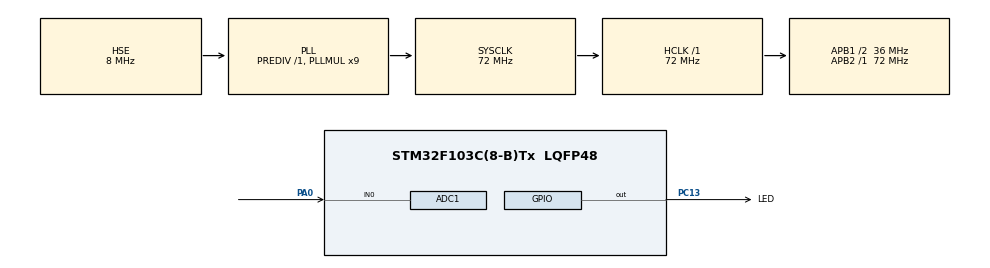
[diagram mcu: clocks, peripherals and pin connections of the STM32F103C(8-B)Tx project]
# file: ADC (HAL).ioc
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ADC1.Channel-0\#ChannelRegularConversion=ADC_CHANNEL_0
ADC1.ExternalTrigConv=ADC_EXTERNALTRIGCONV_T3_TRGO
ADC1.NbrOfConversionFlag=1
ADC1.Rank-0\#ChannelRegularConversion=1
ADC1.SamplingTime-0\#ChannelRegularConversion=ADC_SAMPLETIME_1CYCLE_5
ADC1.master=1
Mcu.Family=STM32F1
Mcu.Name=STM32F103C(8-B)Tx
Mcu.Package=LQFP48
NVIC.ADC1_2_IRQn=true\:0\:0\:false\:false\:true\:true\:true
NVIC.PriorityGroup=NVIC_PRIORITYGROUP_4
PA0-WKUP.Signal=ADCx_IN0
PA13.Mode=Serial_Wire
PA13.Signal=SYS_JTMS-SWDIO
PA14.Mode=Serial_Wire
PA14.Signal=SYS_JTCK-SWCLK
PC13-TAMPER-RTC.GPIO_Label=LED
PC13-TAMPER-RTC.Signal=GPIO_Output
PD0-OSC_IN.Mode=HSE-External-Oscillator
PD0-OSC_IN.Signal=RCC_OSC_IN
PD1-OSC_OUT.Mode=HSE-External-Oscillator
PD1-OSC_OUT.Signal=RCC_OSC_OUT
ProjectManager.HeapSize=0x200
ProjectManager.StackSize=0x400
ProjectManager.TargetToolchain=EWARM V8.32
RCC.ADCPresc=RCC_ADCPCLK2_DIV6
RCC.AHBFreq_Value=72000000
RCC.APB1CLKDivider=RCC_HCLK_DIV2
RCC.APB1Freq_Value=36000000
RCC.APB1TimFreq_Value=72000000
RCC.APB2Freq_Value=72000000
RCC.APB2TimFreq_Value=72000000
RCC.HCLKFreq_Value=72000000
RCC.PLLMUL=RCC_PLL_MUL9
RCC.PLLSourceVirtual=RCC_PLLSOURCE_HSE
RCC.RTCClockSelection=RCC_RTCCLKSOURCE_LSE
RCC.SYSCLKFreq_VALUE=72000000
RCC.SYSCLKSource=RCC_SYSCLKSOURCE_PLLCLK
RCC.USBFreq_Value=72000000
SH.ADCx_IN0.0=ADC1_IN0,IN0
TIM3.AutoReloadPreload=TIM_AUTORELOAD_PRELOAD_ENABLE
TIM3.Period=2000
TIM3.Prescaler=36000
TIM3.TIM_MasterOutputTrigger=TIM_TRGO_UPDATE
VP_TIM3_VS_ClockSourceINT.Mode=Internal
board=custom

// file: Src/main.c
/* USER CODE BEGIN Header */
/**
  ******************************************************************************
  * @file           : main.c
  * @brief          : Main program body
  ******************************************************************************
  * @attention
  *
  * <h2><center>&copy; Copyright (c) 2019 STMicroelectronics.
  * All rights reserved.</center></h2>
  *
  * This software component is licensed by ST under BSD 3-Clause license,
  * the "License"; You may not use this file except in compliance with the
  * License. You may obtain a copy of the License at:
  *                        opensource.org/licenses/BSD-3-Clause
  *
  ******************************************************************************
  */
/* USER CODE END Header */

#include "main.h"

ADC_HandleTypeDef hadc1;

TIM_HandleTypeDef htim3;

void SystemClock_Config(void);
static void MX_GPIO_Init(void);
static void MX_ADC1_Init(void);
static void MX_TIM3_Init(void);

int main(void)
{

  /* MCU Configuration--------------------------------------------------------*/

  /* Reset of all peripherals, Initializes the Flash interface and the Systick. */
  HAL_Init();

  /* Configure the system clock */
  SystemClock_Config();

  /* Initialize all configured peripherals */
  MX_GPIO_Init();
  MX_ADC1_Init();
  MX_TIM3_Init();
  /* USER CODE BEGIN 2 */
  HAL_ADCEx_Calibration_Start(&hadc1);
  HAL_ADC_Start_IT(&hadc1);
  //HAL_TIM_Base_Start_IT(&htim3);
  HAL_TIM_Base_Start(&htim3);
  /* USER CODE END 2 */

  /* Infinite loop */
  while (1)
  {

  }
}

void SystemClock_Config(void)
{
  RCC_OscInitTypeDef RCC_OscInitStruct = {0};
  RCC_ClkInitTypeDef RCC_ClkInitStruct = {0};
  RCC_PeriphCLKInitTypeDef PeriphClkInit = {0};

  /** Initializes the CPU, AHB and APB busses clocks
  */
  RCC_OscInitStruct.OscillatorType = RCC_OSCILLATORTYPE_HSE;
  RCC_OscInitStruct.HSEState = RCC_HSE_ON;
  RCC_OscInitStruct.HSEPredivValue = RCC_HSE_PREDIV_DIV1;
  RCC_OscInitStruct.HSIState = RCC_HSI_ON;
  RCC_OscInitStruct.PLL.PLLState = RCC_PLL_ON;
  RCC_OscInitStruct.PLL.PLLSource = RCC_PLLSOURCE_HSE;
  RCC_OscInitStruct.PLL.PLLMUL = RCC_PLL_MUL9;
  if (HAL_RCC_OscConfig(&RCC_OscInitStruct) != HAL_OK)
  {
    Error_Handler();
  }
  /** Initializes the CPU, AHB and APB busses clocks
  */
  RCC_ClkInitStruct.ClockType = RCC_CLOCKTYPE_HCLK|RCC_CLOCKTYPE_SYSCLK
                              |RCC_CLOCKTYPE_PCLK1|RCC_CLOCKTYPE_PCLK2;
  RCC_ClkInitStruct.SYSCLKSource = RCC_SYSCLKSOURCE_PLLCLK;
  RCC_ClkInitStruct.AHBCLKDivider = RCC_SYSCLK_DIV1;
  RCC_ClkInitStruct.APB1CLKDivider = RCC_HCLK_DIV2;
  RCC_ClkInitStruct.APB2CLKDivider = RCC_HCLK_DIV1;

  if (HAL_RCC_ClockConfig(&RCC_ClkInitStruct, FLASH_LATENCY_2) != HAL_OK)
  {
    Error_Handler();
  }
  PeriphClkInit.PeriphClockSelection = RCC_PERIPHCLK_ADC;
  PeriphClkInit.AdcClockSelection = RCC_ADCPCLK2_DIV6;
  if (HAL_RCCEx_PeriphCLKConfig(&PeriphClkInit) != HAL_OK)
  {
    Error_Handler();
  }
}

static void MX_ADC1_Init(void)
{

  ADC_ChannelConfTypeDef sConfig = {0};

  /** Common config
  */
  hadc1.Instance = ADC1;
  hadc1.Init.ScanConvMode = ADC_SCAN_DISABLE;
  hadc1.Init.ContinuousConvMode = DISABLE;
  hadc1.Init.DiscontinuousConvMode = DISABLE;
  hadc1.Init.ExternalTrigConv = ADC_EXTERNALTRIGCONV_T3_TRGO;
  hadc1.Init.DataAlign = ADC_DATAALIGN_RIGHT;
  hadc1.Init.NbrOfConversion = 1;
  if (HAL_ADC_Init(&hadc1) != HAL_OK)
  {
    Error_Handler();
  }
  /** Configure Regular Channel
  */
  sConfig.Channel = ADC_CHANNEL_0;
  sConfig.Rank = ADC_REGULAR_RANK_1;
  sConfig.SamplingTime = ADC_SAMPLETIME_1CYCLE_5;
  if (HAL_ADC_ConfigChannel(&hadc1, &sConfig) != HAL_OK)
  {
    Error_Handler();
  }

}

static void MX_TIM3_Init(void)
{

  TIM_ClockConfigTypeDef sClockSourceConfig = {0};
  TIM_MasterConfigTypeDef sMasterConfig = {0};

  htim3.Instance = TIM3;
  htim3.Init.Prescaler = 36000;
  htim3.Init.CounterMode = TIM_COUNTERMODE_UP;
  htim3.Init.Period = 2000;
  htim3.Init.ClockDivision = TIM_CLOCKDIVISION_DIV1;
  htim3.Init.AutoReloadPreload = TIM_AUTORELOAD_PRELOAD_ENABLE;
  if (HAL_TIM_Base_Init(&htim3) != HAL_OK)
  {
    Error_Handler();
  }
  sClockSourceConfig.ClockSource = TIM_CLOCKSOURCE_INTERNAL;
  if (HAL_TIM_ConfigClockSource(&htim3, &sClockSourceConfig) != HAL_OK)
  {
    Error_Handler();
  }
  sMasterConfig.MasterOutputTrigger = TIM_TRGO_UPDATE;
  sMasterConfig.MasterSlaveMode = TIM_MASTERSLAVEMODE_DISABLE;
  if (HAL_TIMEx_MasterConfigSynchronization(&htim3, &sMasterConfig) != HAL_OK)
  {
    Error_Handler();
  }

}

static void MX_GPIO_Init(void)
{
  GPIO_InitTypeDef GPIO_InitStruct = {0};

  /* GPIO Ports Clock Enable */
  __HAL_RCC_GPIOC_CLK_ENABLE();
  __HAL_RCC_GPIOD_CLK_ENABLE();
  __HAL_RCC_GPIOA_CLK_ENABLE();

  /*Configure GPIO pin Output Level */
  HAL_GPIO_WritePin(LED_GPIO_Port, LED_Pin, GPIO_PIN_RESET);

  /*Configure GPIO pin : LED_Pin */
  GPIO_InitStruct.Pin = LED_Pin;
  GPIO_InitStruct.Mode = GPIO_MODE_OUTPUT_PP;
  GPIO_InitStruct.Pull = GPIO_NOPULL;
  GPIO_InitStruct.Speed = GPIO_SPEED_FREQ_LOW;
  HAL_GPIO_Init(LED_GPIO_Port, &GPIO_InitStruct);

}

void Error_Handler(void)
{
}

/************************ (C) COPYRIGHT STMicroelectronics *****END OF FILE****/
